# STM32F100 register map
File version: 1.1
CPU: CM3 r1p1, little endian, no MPU, no FPU, 4 interrupt priority bits
Registers are 32-bit, read-write, reset 0x0 unless marked. A register's access mark holds for its fields unless they carry their own. Offsets are from the block's base; [hi:lo] are bit positions; {n}, {i} and the like mark numbered series; 'fields as' and 'values as' point back to an identical list.

## AFIO — Alternate function I/O
Base 0x40010000
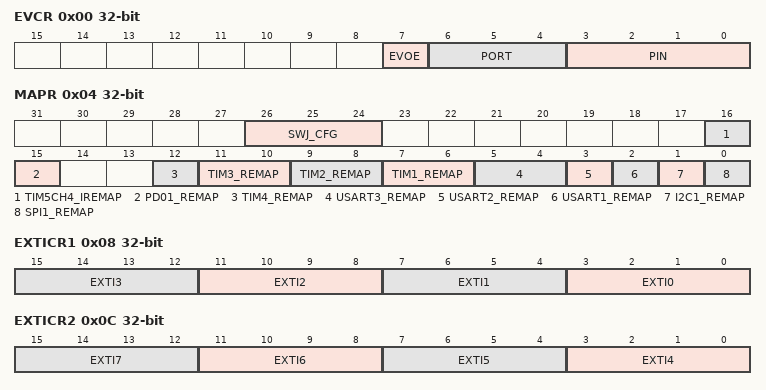
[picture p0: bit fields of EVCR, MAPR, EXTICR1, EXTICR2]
0x00 EVCR — Event Control Register (AFIO_EVCR)
  [7] EVOE — Event Output Enable
  [6:4] PORT — Port selection
  [3:0] PIN — Pin selection
0x04 MAPR access per field — AF remap and debug I/O configuration register (AFIO_MAPR)
  [26:24] SWJ_CFG wo — Serial wire JTAG configuration
  [16] TIM5CH4_IREMAP rw — Set and cleared by software
  [15] PD01_REMAP rw — Port D0/Port D1 mapping on OSCIN/OSCOUT
  [12] TIM4_REMAP rw — TIM4 remapping
  [11:10] TIM3_REMAP rw — TIM3 remapping
  [9:8] TIM2_REMAP rw — TIM2 remapping
  [7:6] TIM1_REMAP rw — TIM1 remapping
  [5:4] USART3_REMAP rw — USART3 remapping
  [3] USART2_REMAP rw — USART2 remapping
  [2] USART1_REMAP rw — USART1 remapping
  [1] I2C1_REMAP rw — I2C1 remapping
  [0] SPI1_REMAP rw — SPI1 remapping
0x08 EXTICR1 — External interrupt configuration register 1 (AFIO_EXTICR1)
  [all] fields
    0=PA (Select PAx as the source input for the EXTIx external interrupt); 1=PB (Select PBx as the source input for the EXTIx external interrupt); 2=PC (Select PCx as the source input for the EXTIx external interrupt); 3=PD (Select PDx as the source input for the EXTIx external interrupt); 4=PE (Select PEx as the source input for the EXTIx external interrupt); 5=PF (Select PFx as the source input for the EXTIx external interrupt); 6=PG (Select PGx as the source input for the EXTIx external interrupt)
  [4n+3:4n] EXTI{n} (n=0..3) — EXTI{n} configuration
0x0C EXTICR2 — External interrupt configuration register 2 (AFIO_EXTICR2)
  [all] fields
    values as the fields of EXTICR1
  [4n-13:4n-16] EXTI{n} (n=4..7) — EXTI{n} configuration
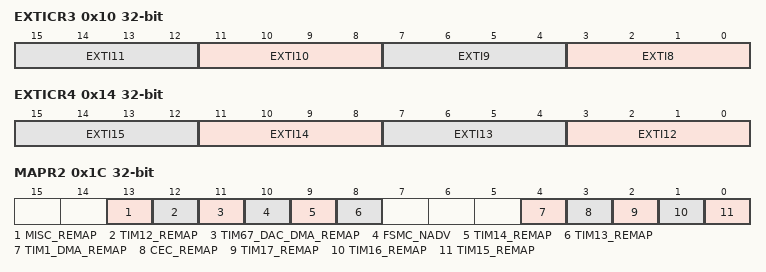
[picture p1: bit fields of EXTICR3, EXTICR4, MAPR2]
0x10 EXTICR3 — External interrupt configuration register 3 (AFIO_EXTICR3)
  [all] fields
    values as the fields of EXTICR1
  [4n-29:4n-32] EXTI{n} (n=8..11) — EXTI{n} configuration
0x14 EXTICR4 — External interrupt configuration register 4 (AFIO_EXTICR4)
  [all] fields
    values as the fields of EXTICR1
  [4n-45:4n-48] EXTI{n} (n=12..15) — EXTI{n} configuration
0x1C MAPR2 — AF remap and debug I/O configuration register
  [13] MISC_REMAP — Miscellaneous features remapping
  [12] TIM12_REMAP — TIM12 remapping
  [11] TIM67_DAC_DMA_REMAP — TIM67_DAC DMA remapping
  [10] FSMC_NADV — NADV connect/disconnect
  [9] TIM14_REMAP — TIM14 remapping
  [8] TIM13_REMAP — TIM13 remapping
  [4] TIM1_DMA_REMAP — TIM1 DMA remapping
  [3] CEC_REMAP — CEC remapping
  [2] TIM17_REMAP — TIM17 remapping
  [1] TIM16_REMAP — TIM16 remapping
  [0] TIM15_REMAP — TIM15 remapping

## EXTI
Base 0x40010400
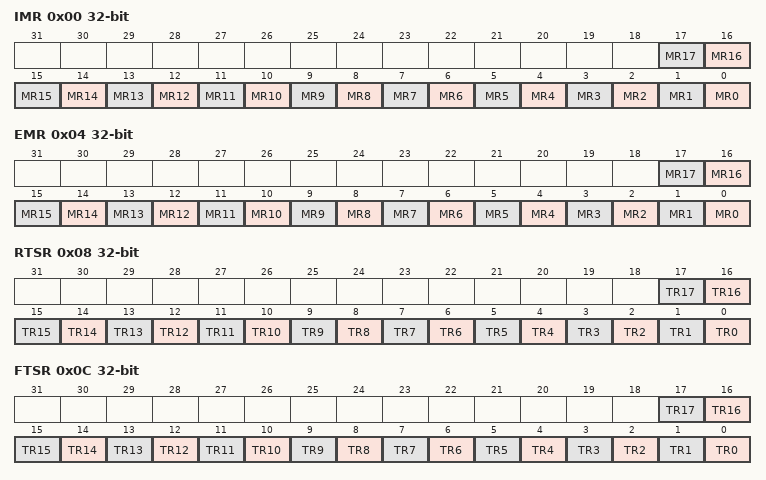
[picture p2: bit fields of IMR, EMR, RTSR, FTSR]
0x00 IMR — Interrupt mask register (EXTI_IMR)
  [n] MR{n} (n=0..17) — Interrupt Mask on line {n}
    0=Masked (Interrupt request line is masked); 1=Unmasked (Interrupt request line is unmasked)
0x04 EMR — Event mask register (EXTI_EMR)
  [n] MR{n} (n=0..17) — Event Mask on line {n}
    0=Masked (Event request line is masked); 1=Unmasked (Event request line is unmasked)
0x08 RTSR — Rising Trigger selection register (EXTI_RTSR)
  [n] TR{n} (n=0..17) — Rising trigger event configuration of line {n}
    0=Disabled (Rising edge trigger is disabled); 1=Enabled (Rising edge trigger is enabled)
0x0C FTSR — Falling Trigger selection register (EXTI_FTSR)
  [n] TR{n} (n=0..17) — Falling trigger event configuration of line {n}
    0=Disabled (Falling edge trigger is disabled); 1=Enabled (Falling edge trigger is enabled)
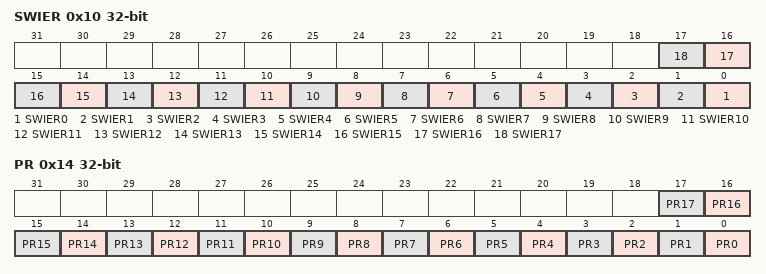
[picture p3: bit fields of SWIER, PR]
0x10 SWIER — Software interrupt event register (EXTI_SWIER)
  [n] SWIER{n} (n=0..17) — Software Interrupt on line {n}
    on write: 1=Pend (Generates an interrupt request)
0x14 PR — Pending register (EXTI_PR)
  [n] PR{n} (n=0..17) write-1-clears — Pending bit {n}
    on read: 0=NotPending (No trigger request occurred); 1=Pending (Selected trigger request occurred) | on write: 1=Clears pending bit
